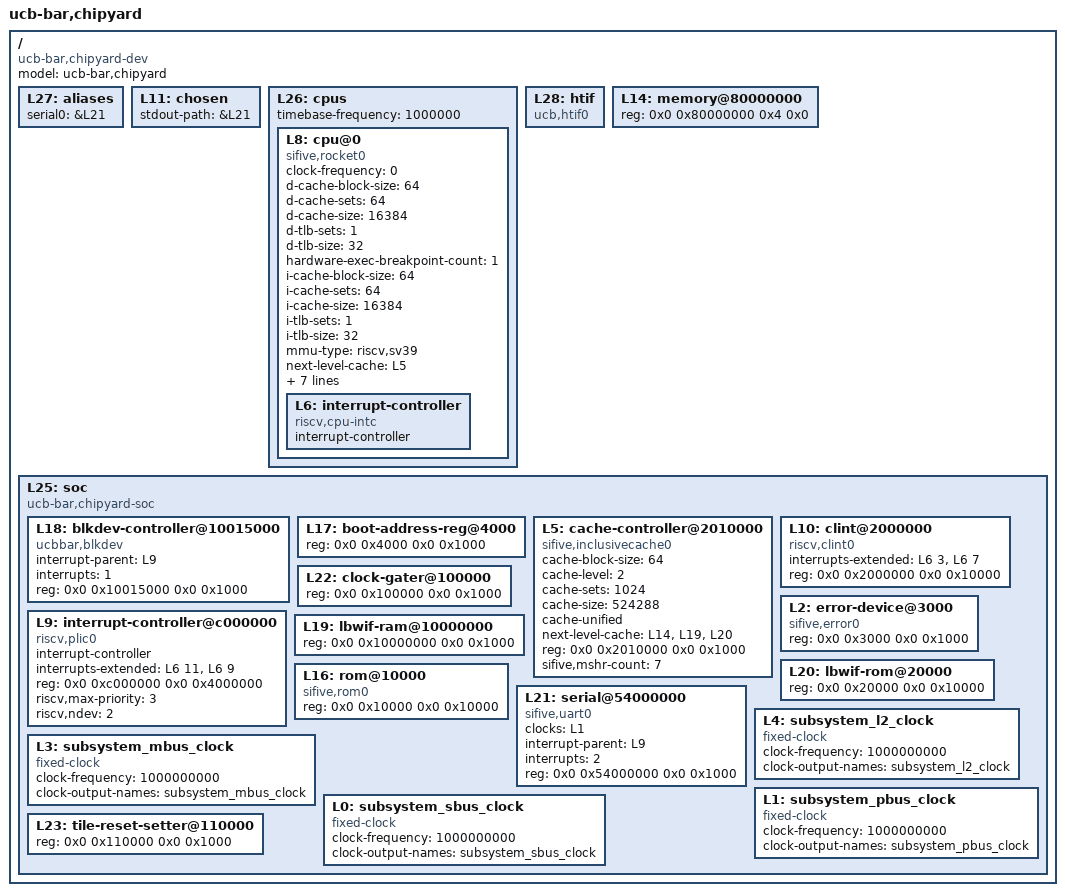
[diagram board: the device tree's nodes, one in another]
/dts-v1/;

/ {
	#address-cells = <2>;
	#size-cells = <2>;
	compatible = "ucb-bar,chipyard-dev";
	model = "ucb-bar,chipyard";
	L27: aliases {
		serial0 = &L21;
	};
	L11: chosen {
		stdout-path = &L21;
	};
	L26: cpus {
		#address-cells = <1>;
		#size-cells = <0>;
		timebase-frequency = <1000000>;
		L8: cpu@0 {
			clock-frequency = <0>;
			compatible = "sifive,rocket0", "riscv";
			d-cache-block-size = <64>;
			d-cache-sets = <64>;
			d-cache-size = <16384>;
			d-tlb-sets = <1>;
			d-tlb-size = <32>;
			device_type = "cpu";
			hardware-exec-breakpoint-count = <1>;
			i-cache-block-size = <64>;
			i-cache-sets = <64>;
			i-cache-size = <16384>;
			i-tlb-sets = <1>;
			i-tlb-size = <32>;
			mmu-type = "riscv,sv39";
			next-level-cache = <&L5>;
			reg = <0x0>;
			riscv,isa = "rv64imafdcZicsr_Zifencei_Zihpm_Xrocket";
			riscv,pmpgranularity = <4>;
			riscv,pmpregions = <8>;
			status = "okay";
			timebase-frequency = <1000000>;
			tlb-split;
			L6: interrupt-controller {
				#interrupt-cells = <1>;
				compatible = "riscv,cpu-intc";
				interrupt-controller;
			};
		};
	};
	L28: htif {
		compatible = "ucb,htif0";
	};
	L14: memory@80000000 {
		device_type = "memory";
		reg = <0x0 0x80000000 0x4 0x0>;
	};
	L25: soc {
		#address-cells = <2>;
		#size-cells = <2>;
		compatible = "ucb-bar,chipyard-soc", "simple-bus";
		ranges;
		L18: blkdev-controller@10015000 {
			compatible = "ucbbar,blkdev";
			interrupt-parent = <&L9>;
			interrupts = <1>;
			reg = <0x0 0x10015000 0x0 0x1000>;
			reg-names = "control";
		};
		L17: boot-address-reg@4000 {
			reg = <0x0 0x4000 0x0 0x1000>;
			reg-names = "control";
		};
		L5: cache-controller@2010000 {
			cache-block-size = <64>;
			cache-level = <2>;
			cache-sets = <1024>;
			cache-size = <524288>;
			cache-unified;
			compatible = "sifive,inclusivecache0", "cache";
			next-level-cache = <&L14 &L19 &L20>;
			reg = <0x0 0x2010000 0x0 0x1000>;
			reg-names = "control";
			sifive,mshr-count = <7>;
		};
		L10: clint@2000000 {
			compatible = "riscv,clint0";
			interrupts-extended = <&L6 3 &L6 7>;
			reg = <0x0 0x2000000 0x0 0x10000>;
			reg-names = "control";
		};
		L22: clock-gater@100000 {
			reg = <0x0 0x100000 0x0 0x1000>;
			reg-names = "control";
		};
		L2: error-device@3000 {
			compatible = "sifive,error0";
			reg = <0x0 0x3000 0x0 0x1000>;
		};
		L9: interrupt-controller@c000000 {
			#interrupt-cells = <1>;
			compatible = "riscv,plic0";
			interrupt-controller;
			interrupts-extended = <&L6 11 &L6 9>;
			reg = <0x0 0xc000000 0x0 0x4000000>;
			reg-names = "control";
			riscv,max-priority = <3>;
			riscv,ndev = <2>;
		};
		L19: lbwif-ram@10000000 {
			reg = <0x0 0x10000000 0x0 0x1000>;
		};
		L20: lbwif-rom@20000 {
			reg = <0x0 0x20000 0x0 0x10000>;
		};
		L16: rom@10000 {
			compatible = "sifive,rom0";
			reg = <0x0 0x10000 0x0 0x10000>;
			reg-names = "mem";
		};
		L21: serial@54000000 {
			clocks = <&L1>;
			compatible = "sifive,uart0";
			interrupt-parent = <&L9>;
			interrupts = <2>;
			reg = <0x0 0x54000000 0x0 0x1000>;
			reg-names = "control";
		};
		L4: subsystem_l2_clock {
			#clock-cells = <0>;
			clock-frequency = <1000000000>;
			clock-output-names = "subsystem_l2_clock";
			compatible = "fixed-clock";
		};
		L3: subsystem_mbus_clock {
			#clock-cells = <0>;
			clock-frequency = <1000000000>;
			clock-output-names = "subsystem_mbus_clock";
			compatible = "fixed-clock";
		};
		L1: subsystem_pbus_clock {
			#clock-cells = <0>;
			clock-frequency = <1000000000>;
			clock-output-names = "subsystem_pbus_clock";
			compatible = "fixed-clock";
		};
		L0: subsystem_sbus_clock {
			#clock-cells = <0>;
			clock-frequency = <1000000000>;
			clock-output-names = "subsystem_sbus_clock";
			compatible = "fixed-clock";
		};
		L23: tile-reset-setter@110000 {
			reg = <0x0 0x110000 0x0 0x1000>;
			reg-names = "control";
		};
	};
};
